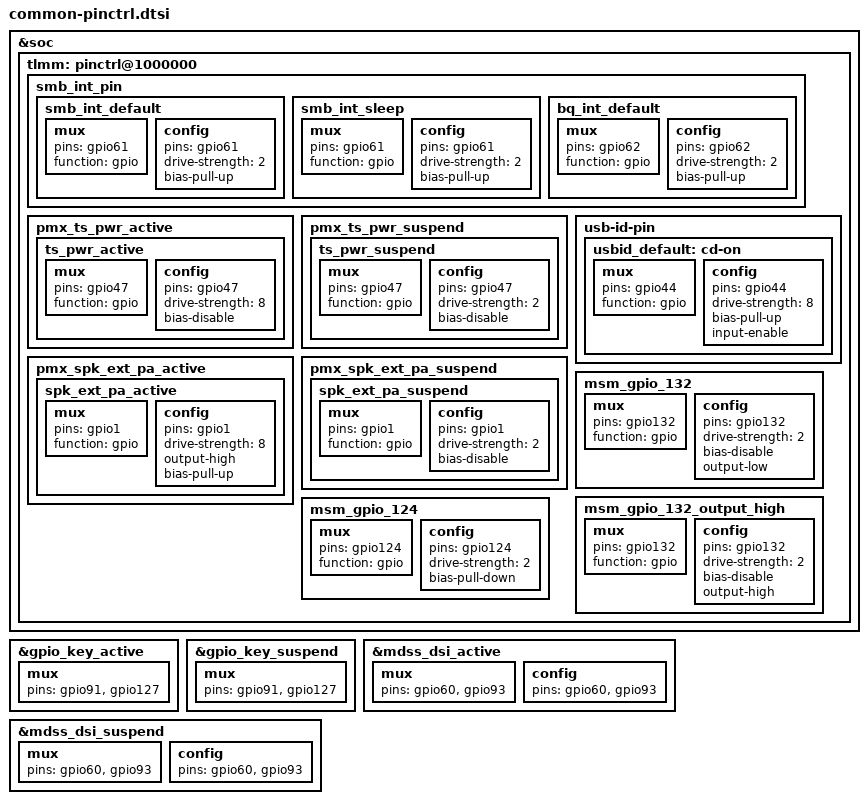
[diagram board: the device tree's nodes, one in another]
/*
 * Copyright (c) 2015, The Linux Foundation. All rights reserved.
 * Copyright (C) 2018 XiaoMi, Inc.
 *
 * This program is free software; you can redistribute it and/or modify
 * it under the terms of the GNU General Public License version 2 and
 * only version 2 as published by the Free Software Foundation.
 *
 * This program is distributed in the hope that it will be useful,
 * but WITHOUT ANY WARRANTY; without even the implied warranty of
 * MERCHANTABILITY or FITNESS FOR A PARTICULAR PURPOSE.  See the
 * GNU General Public License for more details.
 */

&soc {
	tlmm: pinctrl@1000000 {
		smb_int_pin {
			smb_int_default: smb_int_default {
				mux {
					pins = "gpio61";
					function ="gpio";
				};
				config {
					pins = "gpio61";
					drive-strength = <2>;
					bias-pull-up;
				};
			};

			smb_int_sleep: smb_int_sleep {
				mux {
					pins = "gpio61";
					function ="gpio";
				};
				config {
					pins = "gpio61";
					drive-strength = <2>;
					bias-pull-up;
				};
			};

			bq_int_default: bq_int_default {
				mux {
					pins = "gpio62";
					function ="gpio";
				};
				config {
					pins = "gpio62";
					drive-strength = <2>;   /* 2 MA */
					bias-pull-up;           /* PULL UP */
				};
			};
		};

		pmx_ts_pwr_active {
			ts_pwr_active: ts_pwr_active {
				mux {
					pins = "gpio47";
					function = "gpio";
				};

				config {
					pins = "gpio47";
					drive-strength = <8>;
					bias-disable;
				};
			};
		};

		pmx_ts_pwr_suspend {
			ts_pwr_suspend: ts_pwr_suspend {
				mux {
					pins = "gpio47";
					function = "gpio";
				};

				config {
					pins = "gpio47";
					drive-strength = <2>;
					bias-disable;
				};
			};
		};

		usb-id-pin {
			usbid_default: cd-on{
				mux {
					pins = "gpio44";
					function = "gpio";
				};
				config {
					pins = "gpio44";
					drive-strength = <8>;
					bias-pull-up;
					input-enable;
				};
			};
		};

		pmx_spk_ext_pa_active{
			spk_ext_pa_active: spk_ext_pa_active {
				mux {
				pins = "gpio1";
				function = "gpio";
				};

			config {
				pins = "gpio1";
				drive-strength = <8>;
				output-high;
				bias-pull-up;
				};

			};
		};

		pmx_spk_ext_pa_suspend{
			spk_ext_pa_suspend: spk_ext_pa_suspend {
				mux {
				pins = "gpio1";
				function = "gpio";
				};

			config {
				pins = "gpio1";
				drive-strength = <2>;
				bias-disable;
				};
			};
		};

		msm_gpio_132:msm_gpio_132 {
			mux{
				pins="gpio132";
				function= "gpio";
			};
			config {
				pins= "gpio132";
				drive-strength = <2>;
				bias-disable;
				output-low;

			};
		};

		msm_gpio_132_output_high:msm_gpio_132_output_high {
			mux {
				pins = "gpio132";
				function = "gpio";

			};
			config{
				pins = "gpio132";
				drive-strength = <2>;
				bias-disable;
				output-high;
			};

		};

		msm_gpio_124:msm_gpio_124{
			mux{
				pins = "gpio124";
				function = "gpio";
			};
			config{
				pins = "gpio124";
				drive-strength=<2>;
				bias-pull-down;
			};
		};
	};
};	

&gpio_key_active{
	mux {
		pins = "gpio91", "gpio127";
	};
};
&gpio_key_suspend {
	mux {
		pins = "gpio91", "gpio127";
	};
};

&mdss_dsi_active {
	mux {
		pins = "gpio60", "gpio93";
	};
	config {
		pins = "gpio60", "gpio93";
	};
};

&mdss_dsi_suspend {
	mux {
		pins = "gpio60", "gpio93";
		};
	config {
		pins = "gpio60", "gpio93";
	};
};
